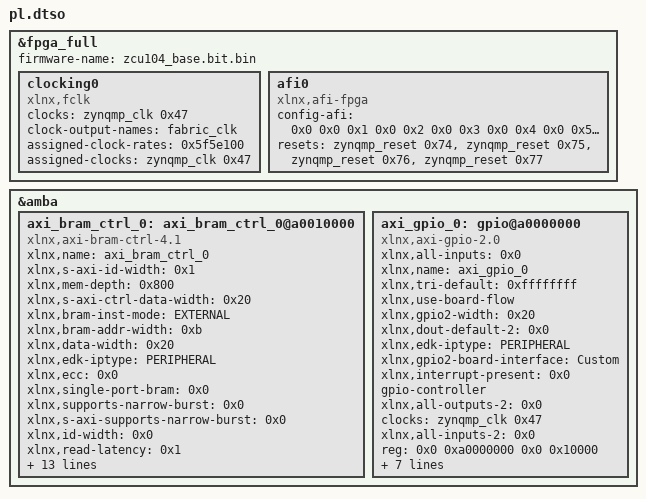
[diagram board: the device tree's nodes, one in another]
/dts-v1/;
/plugin/;

&fpga_full {
        firmware-name = "zcu104_base.bit.bin";

        clocking0: clocking0 {
                clocks = <&zynqmp_clk 0x47>;
                clock-output-names = "fabric_clk";
                #clock-cells = <0x0>;
                assigned-clock-rates = <0x5f5e100>;
                assigned-clocks = <&zynqmp_clk 0x47>;
                compatible = "xlnx,fclk";
        };

        afi0: afi0 {
                config-afi = <0x0 0x0 0x1 0x0 0x2 0x0 0x3 0x0 0x4 0x0 0x5 0x0 0x6 0x0 0x7 0x0 0x8 0x0 0x9 0x0 0xa 0x0 0xb 0x0 0xc 0x0 0xd 0x0 0xe 0xa00 0xf 0x0>;
                resets = <&zynqmp_reset 0x74>,
                 <&zynqmp_reset 0x75>,
                 <&zynqmp_reset 0x76>,
                 <&zynqmp_reset 0x77>;
                compatible = "xlnx,afi-fpga";
        };
};

&amba {

        axi_bram_ctrl_0: axi_bram_ctrl_0@a0010000 {
                xlnx,name = "axi_bram_ctrl_0";
                xlnx,s-axi-id-width = <0x1>;
                xlnx,mem-depth = <0x800>;
                xlnx,s-axi-ctrl-data-width = <0x20>;
                xlnx,bram-inst-mode = "EXTERNAL";
                xlnx,bram-addr-width = <0xb>;
                xlnx,data-width = <0x20>;
                clock-names = "s_axi_aclk";
                xlnx,edk-iptype = "PERIPHERAL";
                xlnx,ecc = <0x0>;
                xlnx,single-port-bram = <0x0>;
                xlnx,supports-narrow-burst = <0x0>;
                xlnx,s-axi-supports-narrow-burst = <0x0>;
                xlnx,id-width = <0x0>;
                xlnx,read-latency = <0x1>;
                xlnx,s-axi-ctrl-addr-width = <0x20>;
                clocks = <&zynqmp_clk 0x47>;
                xlnx,bmg-instance = "EXTERNAL";
                reg = <0x0 0xa0010000 0x0 0x2000>;
                xlnx,ip-name = "axi_bram_ctrl";
                xlnx,fault-inject = <0x0>;
                xlnx,use-ecc = <0x0>;
                xlnx,memory-depth = <0x800>;
                xlnx,rd-cmd-optimization = <0x0>;
                xlnx,ecc-type = <0x0>;
                xlnx,ecc-onoff-reset-value = <0x0>;
                compatible = "xlnx,axi-bram-ctrl-4.1", "xlnx,axi-bram-ctrl";
                xlnx,edk-special = "BRAM_CTRL";
                xlnx,protocol = "AXI4";
        };

        axi_gpio_0: gpio@a0000000 {
                xlnx,all-inputs = <0x0>;
                xlnx,name = "axi_gpio_0";
                xlnx,tri-default = <0xffffffff>;
                xlnx,use-board-flow;
                clock-names = "s_axi_aclk";
                xlnx,gpio2-width = <0x20>;
                xlnx,dout-default-2 = <0x0>;
                xlnx,edk-iptype = "PERIPHERAL";
                xlnx,gpio2-board-interface = "Custom";
                xlnx,interrupt-present = <0x0>;
                device_type = "gpio";
                gpio-controller;
                xlnx,all-outputs-2 = <0x0>;
                clocks = <&zynqmp_clk 0x47>;
                xlnx,all-inputs-2 = <0x0>;
                reg = <0x0 0xa0000000 0x0 0x10000>;
                xlnx,tri-default-2 = <0xffffffff>;
                xlnx,ip-name = "axi_gpio";
                xlnx,is-dual = <0x0>;
                xlnx,dout-default = <0x0>;
                xlnx,gpio-width = <0x4>;
                #gpio-cells = <0x2>;
                xlnx,all-outputs = <0x1>;
                compatible = "xlnx,axi-gpio-2.0", "xlnx,xps-gpio-1.00.a";
                xlnx,gpio-board-interface = "led_4bits";
        };
};

